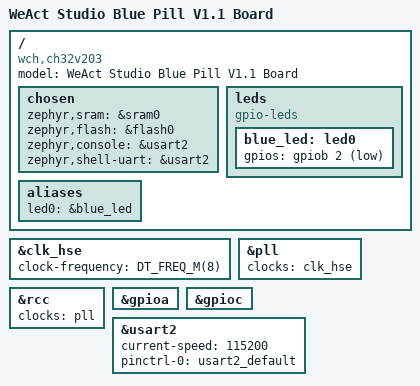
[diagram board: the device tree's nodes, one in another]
/*
 * Copyright (c) 2025 Jianxiong Gu <jianxiong.gu@outlook.com>
 * SPDX-License-Identifier: Apache-2.0
 */

/dts-v1/;

#include <wch/ch32v2/ch32v203c8t.dtsi>
#include <zephyr/dt-bindings/gpio/gpio.h>
#include <zephyr/dt-bindings/input/input-event-codes.h>
#include "bluepill_ch32v203-pinctrl.dtsi"

/ {
	model = "WeAct Studio Blue Pill V1.1 Board";
	compatible = "wch,ch32v203";

	chosen {
		zephyr,sram = &sram0;
		zephyr,flash = &flash0;
		zephyr,console = &usart2;
		zephyr,shell-uart = &usart2;
	};

	leds {
		compatible = "gpio-leds";
		status = "okay";

		blue_led: led0 {
			gpios = <&gpiob 2 GPIO_ACTIVE_LOW>;
		};
	};

	aliases {
		led0 = &blue_led;
	};
};

&clk_hse {
	clock-frequency = <DT_FREQ_M(8)>;
	status = "okay";
};

&pll {
	clocks = <&clk_hse>;
	status = "okay";
};

&rcc {
	clocks = <&pll>;
};

&gpioa {
	status = "okay";
};

&gpioc {
	status = "okay";
};

&usart2 {
	status = "okay";
	current-speed = <115200>;
	pinctrl-0 = <&usart2_default>;
	pinctrl-names = "default";
};
